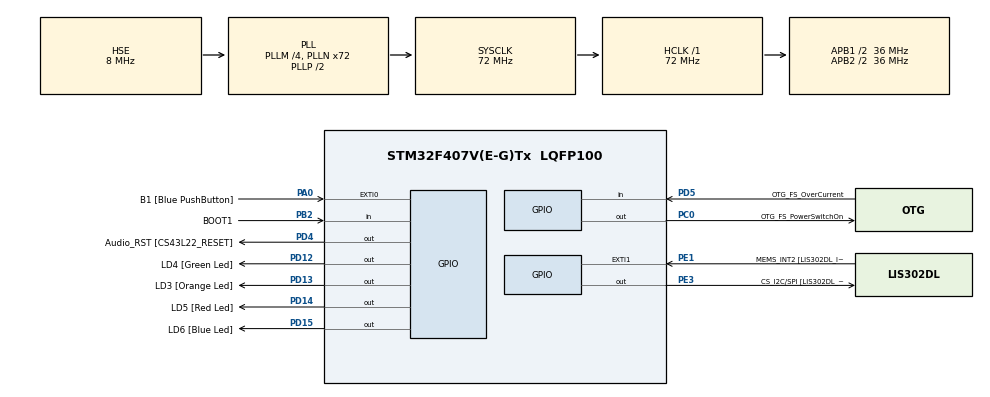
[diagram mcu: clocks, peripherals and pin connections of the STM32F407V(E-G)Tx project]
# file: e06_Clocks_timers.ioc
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Mcu.Family=STM32F4
RCC.PLLSourceVirtual=RCC_PLLSOURCE_HSE
PD12.GPIO_Label=LD4 [Green Led]
PH0-OSC_IN.Signal=RCC_OSC_IN
RCC.CortexFreq_Value=72000000
PD12.GPIO_Speed=GPIO_SPEED_FREQ_LOW
PD15.GPIO_Label=LD6 [Blue Led]
TIM14.AutoReloadPreload=TIM_AUTORELOAD_PRELOAD_ENABLE
PD15.GPIO_Speed=GPIO_SPEED_FREQ_LOW
PC0.GPIO_Label=OTG_FS_PowerSwitchOn
PE1.GPIO_PuPd=GPIO_NOPULL
PD5.Signal=GPIO_Input
PC0.Signal=GPIO_Output
PE1.GPIO_ModeDefaultEXTI=GPIO_MODE_EVT_RISING
RCC.APB1CLKDivider=RCC_HCLK_DIV2
RCC.SYSCLKSource=RCC_SYSCLKSOURCE_PLLCLK
ProjectManager.StackSize=0x400
PA0-WKUP.GPIO_Label=B1 [Blue PushButton]
PA0-WKUP.Signal=GPXTI0
PD13.Signal=GPIO_Output
PD4.GPIO_PuPd=GPIO_NOPULL
PD14.GPIO_Speed=GPIO_SPEED_FREQ_LOW
PC0.GPIO_Speed=GPIO_SPEED_FREQ_LOW
ProjectManager.TargetToolchain=STM32CubeIDE
RCC.HCLKFreq_Value=72000000
PD4.Signal=GPIO_Output
RCC.APB2TimFreq_Value=72000000
PE1.Signal=GPXTI1
RCC.LSE_VALUE=32768
RCC.AHBFreq_Value=72000000
PH0-OSC_IN.Mode=HSE-External-Oscillator
RCC.HSE_VALUE=8000000
NVIC.TIM8_TRG_COM_TIM14_IRQn=true\:0\:0\:false\:false\:true\:true\:true
PB2.Signal=GPIO_Input
board=STM32F407G-DISC1
PD13.GPIO_Speed=GPIO_SPEED_FREQ_LOW
RCC.VCOOutputFreq_Value=144000000
TIM14.Period=4999
PE1.GPIO_Label=MEMS_INT2 [LIS302DL_INT2]
RCC.APB2Freq_Value=36000000
PB2.GPIO_Mode=GPIO_MODE_INPUT
PD4.GPIO_Label=Audio_RST [CS43L22_RESET]
PD4.GPIO_Speed=GPIO_SPEED_FREQ_LOW
PE3.GPIO_PuPd=GPIO_NOPULL
PH1-OSC_OUT.Signal=RCC_OSC_OUT
PD5.GPIO_Mode=GPIO_MODE_INPUT
PD13.GPIO_PuPd=GPIO_NOPULL
PD5.GPIO_PuPd=GPIO_NOPULL
PD14.GPIO_PuPd=GPIO_NOPULL
PD14.GPIO_Label=LD5 [Red Led]
Mcu.Name=STM32F407V(E-G)Tx
PB2.GPIO_PuPd=GPIO_NOPULL
TIM14.Prescaler=7199
PD14.Signal=GPIO_Output
PH1-OSC_OUT.Mode=HSE-External-Oscillator
RCC.48MHZClocksFreq_Value=20571428.57142857
RCC.SYSCLKFreq_VALUE=72000000
PD13.GPIO_Label=LD3 [Orange Led]
Mcu.Package=LQFP100
PE3.GPIO_Speed=GPIO_SPEED_FREQ_LOW
RCC.EnbaleCSS=true
PD12.Signal=GPIO_Output
PD5.GPIO_Label=OTG_FS_OverCurrent
PD15.GPIO_PuPd=GPIO_NOPULL
PB2.GPIO_Label=BOOT1
ProjectManager.HeapSize=0x200
RCC.HSI_VALUE=16000000
RCC.PLLQ=7
NVIC.PriorityGroup=NVIC_PRIORITYGROUP_0
RCC.APB2CLKDivider=RCC_HCLK_DIV2
RCC.PLLM=4
RCC.PLLN=72
RCC.APB1TimFreq_Value=72000000
PE3.Signal=GPIO_Output
PE3.GPIO_Label=CS_I2C/SPI [LIS302DL_CS_I2C/SPI]
VP_TIM14_VS_ClockSourceINT.Mode=Enable_Timer
PC0.GPIO_PuPd=GPIO_NOPULL
RCC.APB1Freq_Value=36000000
PD15.Signal=GPIO_Output
PC0.PinState=GPIO_PIN_SET
PD12.GPIO_PuPd=GPIO_NOPULL

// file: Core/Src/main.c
/* USER CODE BEGIN Header */
/**
  ******************************************************************************
  * @file           : main.c
  * @brief          : Main program body
  ******************************************************************************
  * @attention
  *
  * <h2><center>&copy; Copyright (c) 2021 STMicroelectronics.
  * All rights reserved.</center></h2>
  *
  * This software component is licensed by ST under BSD 3-Clause license,
  * the "License"; You may not use this file except in compliance with the
  * License. You may obtain a copy of the License at:
  *                        opensource.org/licenses/BSD-3-Clause
  *
  ******************************************************************************
  */
/* USER CODE END Header */
#include "main.h"
#include "tim.h"
#include "gpio.h"

void SystemClock_Config(void);

int main(void)
{

  /* MCU Configuration--------------------------------------------------------*/

  /* Reset of all peripherals, Initializes the Flash interface and the Systick. */
  HAL_Init();

  /* Configure the system clock */
  SystemClock_Config();

  /* Initialize all configured peripherals */
  MX_GPIO_Init();
  MX_TIM14_Init();
  /* USER CODE BEGIN 2 */
  HAL_TIM_Base_Start_IT(&htim14);
  /* USER CODE END 2 */

  /* Infinite loop */
  while (1)
  {

  }
}

void SystemClock_Config(void)
{
  RCC_OscInitTypeDef RCC_OscInitStruct = {0};
  RCC_ClkInitTypeDef RCC_ClkInitStruct = {0};

  /** Configure the main internal regulator output voltage
  */
  __HAL_RCC_PWR_CLK_ENABLE();
  __HAL_PWR_VOLTAGESCALING_CONFIG(PWR_REGULATOR_VOLTAGE_SCALE1);
  /** Initializes the RCC Oscillators according to the specified parameters
  * in the RCC_OscInitTypeDef structure.
  */
  RCC_OscInitStruct.OscillatorType = RCC_OSCILLATORTYPE_HSE;
  RCC_OscInitStruct.HSEState = RCC_HSE_ON;
  RCC_OscInitStruct.PLL.PLLState = RCC_PLL_ON;
  RCC_OscInitStruct.PLL.PLLSource = RCC_PLLSOURCE_HSE;
  RCC_OscInitStruct.PLL.PLLM = 4;
  RCC_OscInitStruct.PLL.PLLN = 72;
  RCC_OscInitStruct.PLL.PLLP = RCC_PLLP_DIV2;
  RCC_OscInitStruct.PLL.PLLQ = 7;
  if (HAL_RCC_OscConfig(&RCC_OscInitStruct) != HAL_OK)
  {
    Error_Handler();
  }
  /** Initializes the CPU, AHB and APB buses clocks
  */
  RCC_ClkInitStruct.ClockType = RCC_CLOCKTYPE_HCLK|RCC_CLOCKTYPE_SYSCLK
                              |RCC_CLOCKTYPE_PCLK1|RCC_CLOCKTYPE_PCLK2;
  RCC_ClkInitStruct.SYSCLKSource = RCC_SYSCLKSOURCE_PLLCLK;
  RCC_ClkInitStruct.AHBCLKDivider = RCC_SYSCLK_DIV1;
  RCC_ClkInitStruct.APB1CLKDivider = RCC_HCLK_DIV2;
  RCC_ClkInitStruct.APB2CLKDivider = RCC_HCLK_DIV2;

  if (HAL_RCC_ClockConfig(&RCC_ClkInitStruct, FLASH_LATENCY_2) != HAL_OK)
  {
    Error_Handler();
  }
  /** Enables the Clock Security System
  */
  HAL_RCC_EnableCSS();
}

/* USER CODE BEGIN 4 */
void HAL_TIM_PeriodElapsedCallback(TIM_HandleTypeDef *htim)
{
	if(htim->Instance == TIM14)
	{
		HAL_GPIO_TogglePin(LD5_GPIO_Port, LD5_Pin);

	}
}
/* USER CODE END 4 */

void Error_Handler(void)
{
  __disable_irq();
  while (1)
  {
  }
}

/************************ (C) COPYRIGHT STMicroelectronics *****END OF FILE****/
